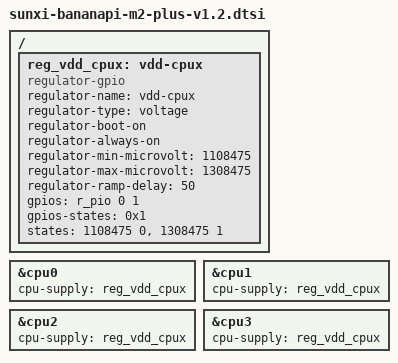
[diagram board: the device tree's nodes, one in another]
#include "sunxi-bananapi-m2-plus.dtsi"
/ {
	reg_vdd_cpux: vdd-cpux {
		compatible = "regulator-gpio";
		regulator-name = "vdd-cpux";
		regulator-type = "voltage";
		regulator-boot-on;
		regulator-always-on;
		regulator-min-microvolt = <1108475>;
		regulator-max-microvolt = <1308475>;
		regulator-ramp-delay = <50>;  
		gpios = <&r_pio 0 1 GPIO_ACTIVE_HIGH>;  
		gpios-states = <0x1>;
		states = <1108475 0>, <1308475 1>;
	};
};
&cpu0 {
	cpu-supply = <&reg_vdd_cpux>;
};
&cpu1 {
	cpu-supply = <&reg_vdd_cpux>;
};
&cpu2 {
	cpu-supply = <&reg_vdd_cpux>;
};
&cpu3 {
	cpu-supply = <&reg_vdd_cpux>;
};
